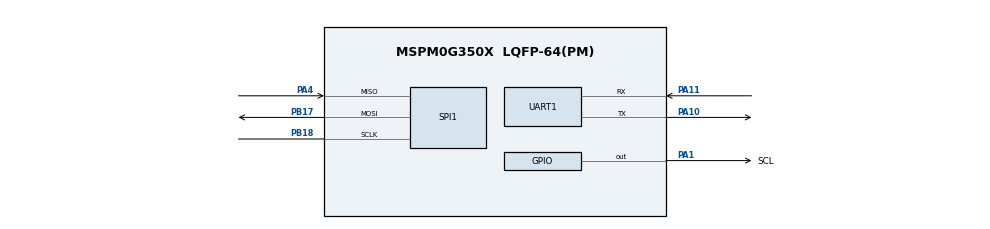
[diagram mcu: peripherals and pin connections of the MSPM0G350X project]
/**
 * @cliArgs --device "MSPM0G350X" --part "Default" --package "LQFP-64(PM)" --product "mspm0_sdk@2.02.00.05"
 * @versions {"tool":"1.21.1+3772"}
 */

/**
 * Import the modules used in this configuration.
 */
const GPIO    = scripting.addModule("/ti/driverlib/GPIO", {}, false);
const GPIO1   = GPIO.addInstance();
const GPIO2   = GPIO.addInstance();
const SPI     = scripting.addModule("/ti/driverlib/SPI", {}, false);
const SPI1    = SPI.addInstance();
const SYSCTL  = scripting.addModule("/ti/driverlib/SYSCTL");
const SYSTICK = scripting.addModule("/ti/driverlib/SYSTICK");
const TIMER   = scripting.addModule("/ti/driverlib/TIMER", {}, false);
const TIMER1  = TIMER.addInstance();
const UART    = scripting.addModule("/ti/driverlib/UART", {}, false);
const UART1   = UART.addInstance();

/**
 * Write custom configuration values to the imported modules.
 */
const gate7  = system.clockTree["MFCLKGATE"];
gate7.enable = true;

GPIO1.$name                          = "CS";
GPIO1.associatedPins[0].$name        = "PIN";
GPIO1.associatedPins[0].assignedPort = "PORTA";
GPIO1.associatedPins[0].assignedPin  = "2";

const Board = scripting.addModule("/ti/driverlib/Board", {}, false);

GPIO2.$name                          = "IIC_Software";
GPIO2.port                           = "PORTA";
GPIO2.associatedPins.create(2);
GPIO2.associatedPins[0].$name        = "SCL";
GPIO2.associatedPins[0].initialValue = "SET";
GPIO2.associatedPins[0].ioStructure  = "OD";
GPIO2.associatedPins[0].assignedPin  = "1";
GPIO2.associatedPins[0].pin.$assign  = "PA1";
GPIO2.associatedPins[1].$name        = "SDA";
GPIO2.associatedPins[1].initialValue = "SET";
GPIO2.associatedPins[1].ioStructure  = "OD";
GPIO2.associatedPins[1].assignedPin  = "0";

SPI1.$name                              = "SPI";
SPI1.polarity                           = "1";
SPI1.phase                              = "1";
SPI1.targetBitRate                      = 2000000;
SPI1.peripheral.$assign                 = "SPI0";
SPI1.peripheral.sclkPin.$assign         = "PB18";
SPI1.peripheral.mosiPin.$assign         = "PB17";
SPI1.peripheral.misoPin.$assign         = "PA4";
SPI1.sclkPinConfig.direction            = scripting.forceWrite("OUTPUT");
SPI1.sclkPinConfig.onlyInternalResistor = scripting.forceWrite(false);
SPI1.sclkPinConfig.passedPeripheralType = scripting.forceWrite("Digital");
SPI1.sclkPinConfig.$name                = "ti_driverlib_gpio_GPIOPinGeneric2";
SPI1.mosiPinConfig.direction            = scripting.forceWrite("OUTPUT");
SPI1.mosiPinConfig.hideOutputInversion  = scripting.forceWrite(false);
SPI1.mosiPinConfig.onlyInternalResistor = scripting.forceWrite(false);
SPI1.mosiPinConfig.passedPeripheralType = scripting.forceWrite("Digital");
SPI1.mosiPinConfig.$name                = "ti_driverlib_gpio_GPIOPinGeneric3";
SPI1.misoPinConfig.onlyInternalResistor = scripting.forceWrite(false);
SPI1.misoPinConfig.passedPeripheralType = scripting.forceWrite("Digital");
SPI1.misoPinConfig.$name                = "ti_driverlib_gpio_GPIOPinGeneric4";
SPI1.cs0PinConfig.direction             = scripting.forceWrite("OUTPUT");
SPI1.cs0PinConfig.hideOutputInversion   = scripting.forceWrite(false);
SPI1.cs0PinConfig.onlyInternalResistor  = scripting.forceWrite(false);
SPI1.cs0PinConfig.passedPeripheralType  = scripting.forceWrite("Digital");
SPI1.cs0PinConfig.$name                 = "ti_driverlib_gpio_GPIOPinGeneric5";

SYSCTL.forceDefaultClkConfig = true;
SYSCTL.clockTreeEn           = true;

SYSTICK.periodEnable      = true;
SYSTICK.systickEnable     = true;
SYSTICK.interruptPriority = "0";
SYSTICK.period            = 32;

TIMER1.timerClkDiv        = 4;
TIMER1.timerClkPrescale   = 80;
TIMER1.timerPeriod        = "100us";
TIMER1.timerStartTimer    = true;
TIMER1.timerMode          = "PERIODIC";
TIMER1.interrupts         = ["ZERO"];
TIMER1.$name              = "TIMER_1";
TIMER1.peripheral.$assign = "TIMA1";

UART1.$name                    = "UART_0";
UART1.uartClkSrc               = "MFCLK";
UART1.enabledInterrupts        = ["RX"];
UART1.targetBaudRate           = 115200;
UART1.peripheral.$assign       = "UART0";
UART1.peripheral.rxPin.$assign = "PA11";
UART1.peripheral.txPin.$assign = "PA10";
UART1.txPinConfig.$name        = "ti_driverlib_gpio_GPIOPinGeneric0";
UART1.rxPinConfig.$name        = "ti_driverlib_gpio_GPIOPinGeneric1";

/**
 * Pinmux solution for unlocked pins/peripherals. This ensures that minor changes to the automatic solver in a future
 * version of the tool will not impact the pinmux you originally saw.  These lines can be completely deleted in order to
 * re-solve from scratch.
 */
GPIO1.associatedPins[0].pin.$suggestSolution = "PA2";
Board.peripheral.$suggestSolution            = "DEBUGSS";
Board.peripheral.swclkPin.$suggestSolution   = "PA20";
Board.peripheral.swdioPin.$suggestSolution   = "PA19";
GPIO2.associatedPins[1].pin.$suggestSolution = "PA0";
SPI1.peripheral.cs0Pin.$suggestSolution      = "PA8";
